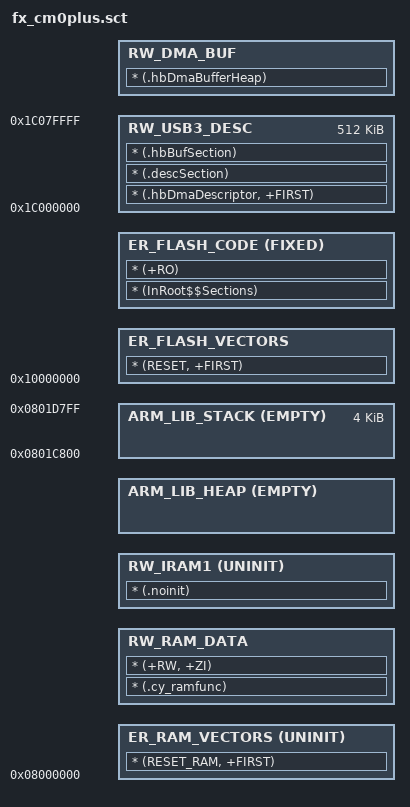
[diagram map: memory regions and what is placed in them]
#! armclang -x assembler-with-cpp -E --target=arm-arm-none-eabi
; The first line specifies a preprocessor command that the linker invokes
; to pass a scatter file through a C preprocessor.

;*******************************************************************************
;* \file fx_cm0plus.sct
;* \version 1.00
;*
;* Linker file for the ARMCC.
;*
;* The main purpose of the linker script is to describe how the sections in the
;* input files should be mapped into the output file, and to control the memory
;* layout of the output file.
;*
;* \note The entry point location is fixed and starts at 0x10000000. The valid
;* application image should be placed there.
;*
;* \note The linker files included with the PDL template projects must be
;* generic and handle all common use cases. Your project may not use every
;* section defined in the linker files. In that case you may see the warnings
;* during the build process: L6314W (no section matches pattern) and/or L6329W
;* (pattern only matches removed unused sections). In your project, you can
;* suppress the warning by passing the "--diag_suppress=L6314W,L6329W" option to
;* the linker, simply comment out or remove the relevant code in the linker
;* file.
;*
;*******************************************************************************
;* \copyright
;* Copyright 2021-2022 Cypress Semiconductor Corporation
;* SPDX-License-Identifier: Apache-2.0
;*
;* Licensed under the Apache License, Version 2.0 (the "License");
;* you may not use this file except in compliance with the License.
;* You may obtain a copy of the License at
;*
;*     http://www.apache.org/licenses/LICENSE-2.0
;*
;* Unless required by applicable law or agreed to in writing, software
;* distributed under the License is distributed on an "AS IS" BASIS,
;* WITHOUT WARRANTIES OR CONDITIONS OF ANY KIND, either express or implied.
;* See the License for the specific language governing permissions and
;* limitations under the License.
;******************************************************************************/

; The defines below describe the location and size of blocks of memory in the target.
; Use these defines to specify the memory regions available for allocation.
;
; The following defines control RAM and flash memory allocation for the CM0+ core.
; You can change the memory allocation by editing the RAM and Flash defines.
; Note that 2 KB of RAM (at the end of the SRAM) are reserved for system use.
; Using this memory region for other purposes will lead to unexpected behavior.
;
; We have 512 KB of High BandWidth Buffer RAM starting from address 0x1C000000.
; The DMA descriptors (.hbDmaDescriptor section) must be placed first in this region.
; The initialized data arrays (.descSection section) are placed after this.
; The un-initialized data buffers (.hbBufSection) and DMA buffer heap (.hbDmaBufferHeap) are placed after this.
;;
; RAM
#define RAM_START               0x08000000
#define RAM_SIZE                0x0001D800
; Flash
#define FLASH_START             0x10000000
#define FLASH_SIZE              0x00080000
;HB-SRAM
#define HBDMARAM_START          0x1C000000
#define HBDMARAM_SIZE           0x00080000

; The size of the stack section at the end of CM0+ SRAM
#define STACK_SIZE              0x00001000

; Cortex-M0+ application flash area
LR_IROM1 FLASH_START FLASH_SIZE
{
    ER_FLASH_VECTORS +0
    {
        * (RESET, +FIRST)
    }

    ER_FLASH_CODE +0 FIXED
    {
        * (InRoot$$Sections)
        * (+RO)
    }

    ER_RAM_VECTORS RAM_START UNINIT
    {
        * (RESET_RAM, +FIRST)
    }

    RW_RAM_DATA +0
    {
        * (.cy_ramfunc)
        * (+RW, +ZI)
    }

    ; Place variables in the section that should not be initialized during the
    ; device startup.
    RW_IRAM1 +0 UNINIT
    {
        * (.noinit)
    }

    ; Application heap area (HEAP)
    ARM_LIB_HEAP  +0 EMPTY ((RAM_START+RAM_SIZE)-AlignExpr(ImageLimit(RW_IRAM1), 8)-STACK_SIZE)
    {
    }

    ; Stack region growing down
    ARM_LIB_STACK (RAM_START+RAM_SIZE) EMPTY -STACK_SIZE
    {
    }

    ; Place DMA descriptor array (first), USB descriptors and other data buffers in the HBDMARAM section.
    RW_USB3_DESC HBDMARAM_START HBDMARAM_SIZE
    {
        * (.hbDmaDescriptor, +FIRST)
        * (.descSection)
        * (.hbBufSection)
    }

    ; Place the DMA buffer heap last in the HBDMARAM section at a 64-byte aligned address.
    RW_DMA_BUF +0 ALIGN 64
    {
        * (.hbDmaBufferHeap)
    }
}


/* The following symbols used by the cymcuelftool. */
/* Flash */
#define __cy_memory_0_start    0x10000000
#define __cy_memory_0_length   0x00080000
#define __cy_memory_0_row_size 0x200

/* Supervisory Flash */
#define __cy_memory_2_start    0x16000000
#define __cy_memory_2_length   0x8000
#define __cy_memory_2_row_size 0x200

/* XIP */
#define __cy_memory_3_start    0x18000000
#define __cy_memory_3_length   0x08000000
#define __cy_memory_3_row_size 0x200

/* eFuse */
#define __cy_memory_4_start    0x90700000
#define __cy_memory_4_length   0x100000
#define __cy_memory_4_row_size 1


/* [] END OF FILE */
